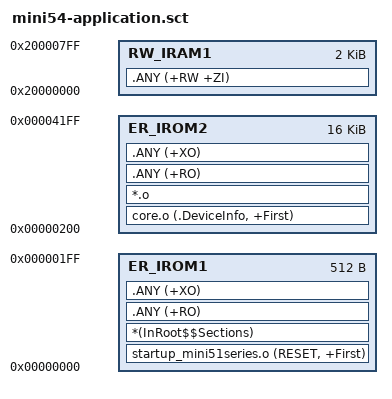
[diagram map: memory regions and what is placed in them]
; *************************************************************
; *** Scatter-Loading Description File generated by uVision ***
; *************************************************************

LR_IROM1 0x00000000 0x00004000  {    ; load region size_region
  ER_IROM1 0x00000000 0x00000200  {  ; load address = execution address
   startup_mini51series.o (RESET, +First)
   *(InRoot$$Sections)
   .ANY (+RO)
   .ANY (+XO)
  }
  ER_IROM2 0x00000200 0x00004000  {  ; load address = execution address
   core.o (.DeviceInfo, +First)
   *.o
   .ANY (+RO)
   .ANY (+XO)
  }
  RW_IRAM1 0x20000000 0x00000800  {  ; RW data
   .ANY (+RW +ZI)
  }
}
